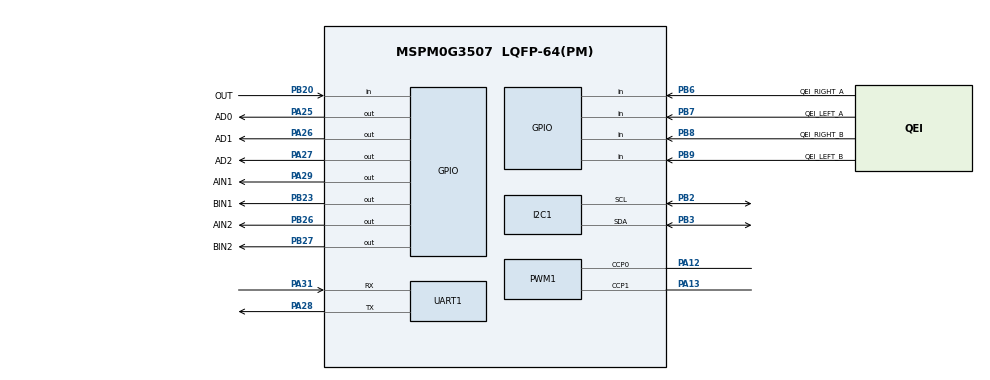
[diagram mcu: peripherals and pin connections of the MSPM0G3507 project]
/**
 * MSPM0G3507 line tracking + PID minimum hardware configuration.
 * Pin mapping is extracted from C:\Users\l2025\workspace_ccstheia\2024H.
 */
//@cliArgs --device "MSPM0G350X" --package "LQFP-64(PM)" --part "Default"
//@v2CliArgs --device "MSPM0G3507" --package "LQFP-64(PM)"
// @cliArgs --board /ti/boards/LP_MSPM0G3507 --rtos nortos

const GPIO   = scripting.addModule("/ti/driverlib/GPIO", {}, false);
const GPIO1  = GPIO.addInstance();
const GPIO2  = GPIO.addInstance();
const GPIO3  = GPIO.addInstance();
const I2C    = scripting.addModule("/ti/driverlib/I2C", {}, false);
const I2C1   = I2C.addInstance();
const PWM    = scripting.addModule("/ti/driverlib/PWM", {}, false);
const PWM1   = PWM.addInstance();
const SYSCTL = scripting.addModule("/ti/driverlib/SYSCTL");
const TIMER  = scripting.addModule("/ti/driverlib/TIMER", {}, false);
const TIMER1 = TIMER.addInstance();
const UART   = scripting.addModule("/ti/driverlib/UART", {}, false);
const UART1  = UART.addInstance();

const Board = scripting.addModule("/ti/driverlib/Board", {}, false);

GPIO1.$name                         = "GPIO_MOTOR";
GPIO1.associatedPins.create(4);
GPIO1.associatedPins[0].$name       = "AIN1";
GPIO1.associatedPins[0].pin.$assign = "PA29";
GPIO1.associatedPins[1].$name       = "AIN2";
GPIO1.associatedPins[1].pin.$assign = "PB26";
GPIO1.associatedPins[2].$name       = "BIN1";
GPIO1.associatedPins[2].pin.$assign = "PB23";
GPIO1.associatedPins[3].$name       = "BIN2";
GPIO1.associatedPins[3].pin.$assign = "PB27";

GPIO2.$name                         = "GPIO_SENSOR";
GPIO2.associatedPins.create(4);
GPIO2.associatedPins[0].$name       = "AD0";
GPIO2.associatedPins[0].pin.$assign = "PA25";
GPIO2.associatedPins[1].$name       = "AD1";
GPIO2.associatedPins[1].pin.$assign = "PA26";
GPIO2.associatedPins[2].$name       = "AD2";
GPIO2.associatedPins[2].pin.$assign = "PA27";
GPIO2.associatedPins[3].$name       = "OUT";
GPIO2.associatedPins[3].direction   = "INPUT";
GPIO2.associatedPins[3].pin.$assign = "PB20";

GPIO3.$name                              = "GPIO_ENCODER";
GPIO3.associatedPins.create(4);
GPIO3.associatedPins[0].$name            = "QEI_LEFT_A";
GPIO3.associatedPins[0].direction        = "INPUT";
GPIO3.associatedPins[0].interruptEn      = true;
GPIO3.associatedPins[0].internalResistor = "PULL_UP";
GPIO3.associatedPins[0].polarity         = "RISE_FALL";
GPIO3.associatedPins[0].pin.$assign      = "PB7";
GPIO3.associatedPins[1].$name            = "QEI_RIGHT_A";
GPIO3.associatedPins[1].direction        = "INPUT";
GPIO3.associatedPins[1].interruptEn      = true;
GPIO3.associatedPins[1].internalResistor = "PULL_UP";
GPIO3.associatedPins[1].polarity         = "RISE_FALL";
GPIO3.associatedPins[1].pin.$assign      = "PB6";
GPIO3.associatedPins[2].$name            = "QEI_LEFT_B";
GPIO3.associatedPins[2].direction        = "INPUT";
GPIO3.associatedPins[2].internalResistor = "PULL_UP";
GPIO3.associatedPins[2].pin.$assign      = "PB9";
GPIO3.associatedPins[3].$name            = "QEI_RIGHT_B";
GPIO3.associatedPins[3].direction        = "INPUT";
GPIO3.associatedPins[3].internalResistor = "PULL_UP";
GPIO3.associatedPins[3].pin.$assign      = "PB8";

I2C1.$name                             = "OLED";
I2C1.basicEnableController             = true;
I2C1.advDigitalGlitchFilter            = "CLOCKS_1";
I2C1.advControllerRXFIFOTRIG           = "BYTES_8";
I2C1.advControllerTXFIFOTRIG           = "BYTES_7";
I2C1.enableDMAEvent1                   = false;
I2C1.enableDMAEvent2                   = false;
I2C1.peripheral.$assign                = "I2C1";
I2C1.peripheral.sdaPin.$assign         = "PB3";
I2C1.peripheral.sclPin.$assign         = "PB2";
I2C1.sdaPinConfig.$name                = "ti_driverlib_gpio_GPIOPinGeneric2";
I2C1.sdaPinConfig.hideOutputInversion  = scripting.forceWrite(false);
I2C1.sdaPinConfig.onlyInternalResistor = scripting.forceWrite(false);
I2C1.sdaPinConfig.passedPeripheralType = scripting.forceWrite("Digital");
I2C1.sdaPinConfig.enableConfig         = true;
I2C1.sdaPinConfig.internalResistor     = "PULL_UP";
I2C1.sclPinConfig.$name                = "ti_driverlib_gpio_GPIOPinGeneric3";
I2C1.sclPinConfig.hideOutputInversion  = scripting.forceWrite(false);
I2C1.sclPinConfig.onlyInternalResistor = scripting.forceWrite(false);
I2C1.sclPinConfig.passedPeripheralType = scripting.forceWrite("Digital");
I2C1.sclPinConfig.enableConfig         = true;
I2C1.sclPinConfig.internalResistor     = "PULL_UP";

PWM1.$name                              = "PWM_MOTOR";
PWM1.pwmMode                            = "EDGE_ALIGN_UP";
PWM1.timerCount                         = 2000;
PWM1.peripheral.$assign                 = "TIMG0";
PWM1.peripheral.ccp0Pin.$assign         = "PA12";
PWM1.peripheral.ccp1Pin.$assign         = "PA13";
PWM1.PWM_CHANNEL_0.$name                = "ti_driverlib_pwm_PWMTimerCC0";
PWM1.PWM_CHANNEL_1.$name                = "ti_driverlib_pwm_PWMTimerCC1";
PWM1.ccp0PinConfig.direction            = scripting.forceWrite("OUTPUT");
PWM1.ccp0PinConfig.hideOutputInversion  = scripting.forceWrite(false);
PWM1.ccp0PinConfig.onlyInternalResistor = scripting.forceWrite(false);
PWM1.ccp0PinConfig.passedPeripheralType = scripting.forceWrite("Digital");
PWM1.ccp0PinConfig.$name                = "ti_driverlib_gpio_GPIOPinGeneric0";
PWM1.ccp1PinConfig.direction            = scripting.forceWrite("OUTPUT");
PWM1.ccp1PinConfig.hideOutputInversion  = scripting.forceWrite(false);
PWM1.ccp1PinConfig.onlyInternalResistor = scripting.forceWrite(false);
PWM1.ccp1PinConfig.passedPeripheralType = scripting.forceWrite("Digital");
PWM1.ccp1PinConfig.$name                = "ti_driverlib_gpio_GPIOPinGeneric1";

SYSCTL.forceDefaultClkConfig = true;
SYSCTL.clockTreeEn           = true;

TIMER1.$name            = "TIMER_0";
TIMER1.interrupts       = ["ZERO"];
TIMER1.timerMode        = "PERIODIC";
TIMER1.timerPeriod      = "10 ms";
TIMER1.timerClkPrescale = 256;

UART1.$name                    = "IMU601";
UART1.targetBaudRate           = 115200;
UART1.enabledInterrupts        = ["RX"];
UART1.peripheral.$assign       = "UART0";
UART1.peripheral.rxPin.$assign = "PA31";
UART1.peripheral.txPin.$assign = "PA28";

Board.peripheral.$suggestSolution          = "DEBUGSS";
Board.peripheral.swclkPin.$suggestSolution = "PA20";
Board.peripheral.swdioPin.$suggestSolution = "PA19";
TIMER1.peripheral.$suggestSolution         = "TIMA0";
UART1.peripheral.$suggestSolution          = "UART0";
